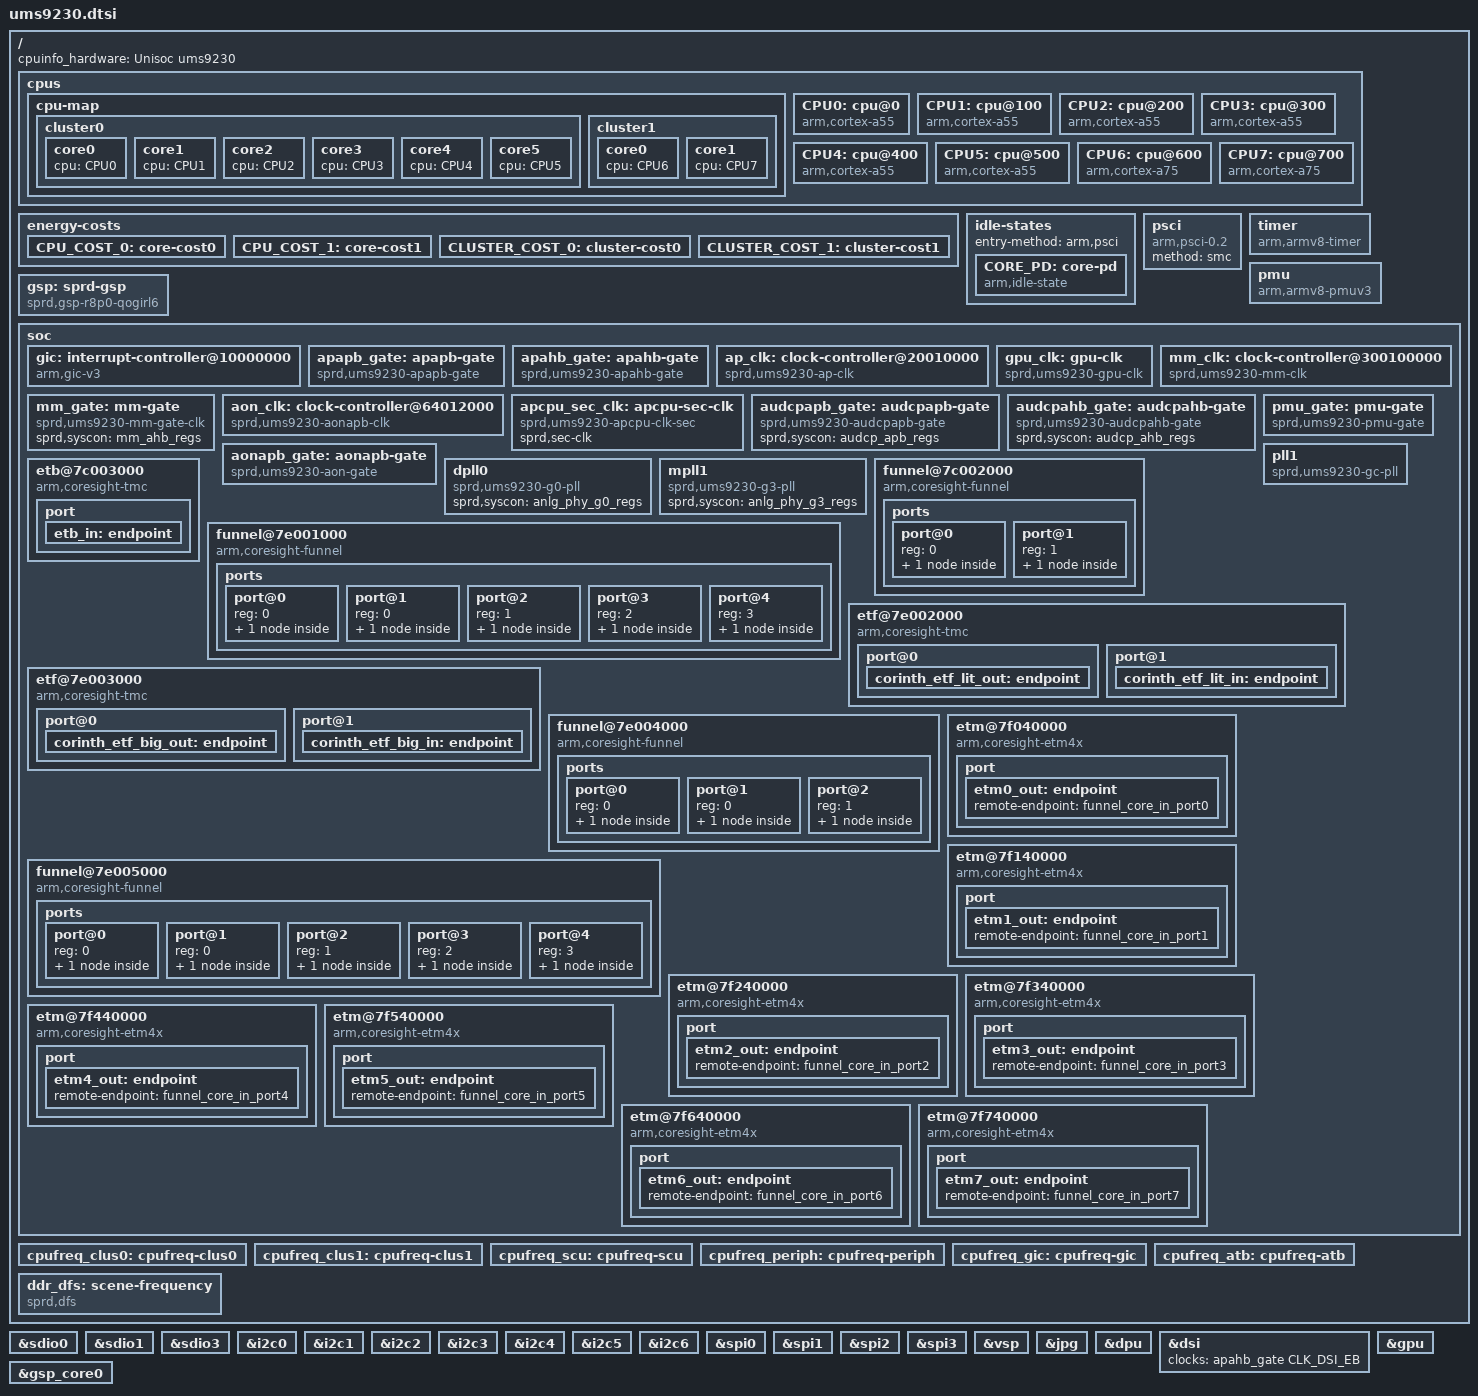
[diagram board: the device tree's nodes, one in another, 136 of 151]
// SPDX-License-Identifier: GPL-2.0-only
/*
 * Unisoc Qogirl6 platform DTS file
 *
 * Copyright (C) 2020, Unisoc Inc.
 */

#include <dt-bindings/interrupt-controller/arm-gic.h>
#include <dt-bindings/clock/sprd,ums9230-clk.h>
#include "qogirl6.dtsi"

/ {
	cpuinfo_hardware = "Unisoc ums9230";

	cpus {
		#address-cells = <2>;
		#size-cells = <0>;

		cpu-map {
			cluster0 {
				core0 {
					cpu = <&CPU0>;
				};
				core1 {
					cpu = <&CPU1>;
				};
				core2 {
					cpu = <&CPU2>;
				};
				core3 {
					cpu = <&CPU3>;
				};
				core4 {
					cpu = <&CPU4>;
				};
				core5 {
					cpu = <&CPU5>;
				};
			};
			cluster1 {
				core0 {
					cpu = <&CPU6>;
				};
				core1 {
					cpu = <&CPU7>;
				};
			};
		};

		CPU0: cpu@0 {
			device_type = "cpu";
			compatible = "arm,cortex-a55";
			reg = <0x0 0x0>;
			enable-method = "psci";
			cpu-idle-states = <&CORE_PD>;
			sched-energy-costs = <&CPU_COST_0 &CLUSTER_COST_0>;
			capacity-dmips-mhz = <544>;
			cpufreq-data-v1 = <&cpufreq_clus0>;
		};
		CPU1: cpu@100 {
			device_type = "cpu";
			compatible = "arm,cortex-a55";
			reg = <0x0 0x100>;
			enable-method = "psci";
			cpu-idle-states = <&CORE_PD>;
			sched-energy-costs = <&CPU_COST_0 &CLUSTER_COST_0>;
			capacity-dmips-mhz = <544>;
			cpufreq-data-v1 = <&cpufreq_clus0>;
		};
		CPU2: cpu@200 {
			device_type = "cpu";
			compatible = "arm,cortex-a55";
			reg = <0x0 0x200>;
			enable-method = "psci";
			cpu-idle-states = <&CORE_PD>;
			sched-energy-costs = <&CPU_COST_0 &CLUSTER_COST_0>;
			capacity-dmips-mhz = <544>;
			cpufreq-data-v1 = <&cpufreq_clus0>;
		};
		CPU3: cpu@300 {
			device_type = "cpu";
			compatible = "arm,cortex-a55";
			reg = <0x0 0x300>;
			enable-method = "psci";
			cpu-idle-states = <&CORE_PD>;
			sched-energy-costs = <&CPU_COST_0 &CLUSTER_COST_0>;
			capacity-dmips-mhz = <544>;
			cpufreq-data-v1 = <&cpufreq_clus0>;
		};
		CPU4: cpu@400 {
			device_type = "cpu";
			compatible = "arm,cortex-a55";
			reg = <0x0 0x400>;
			enable-method = "psci";
			cpu-idle-states = <&CORE_PD>;
			sched-energy-costs = <&CPU_COST_0 &CLUSTER_COST_0>;
			capacity-dmips-mhz = <544>;
			cpufreq-data-v1 = <&cpufreq_clus0>;
		};
		CPU5: cpu@500 {
			device_type = "cpu";
			compatible = "arm,cortex-a55";
			reg = <0x0 0x500>;
			enable-method = "psci";
			cpu-idle-states = <&CORE_PD>;
			sched-energy-costs = <&CPU_COST_0 &CLUSTER_COST_0>;
			capacity-dmips-mhz = <544>;
			cpufreq-data-v1 = <&cpufreq_clus0>;
		};
		CPU6: cpu@600 {
			device_type = "cpu";
			compatible = "arm,cortex-a75";
			reg = <0x0 0x600>;
			enable-method = "psci";
			cpu-idle-states = <&CORE_PD>;
			sched-energy-costs = <&CPU_COST_1 &CLUSTER_COST_1>;
			capacity-dmips-mhz = <1024>;
			cpufreq-data-v1 = <&cpufreq_clus1>;
		};
		CPU7: cpu@700 {
			device_type = "cpu";
			compatible = "arm,cortex-a75";
			reg = <0x0 0x700>;
			enable-method = "psci";
			cpu-idle-states = <&CORE_PD>;
			sched-energy-costs = <&CPU_COST_1 &CLUSTER_COST_1>;
			capacity-dmips-mhz = <1024>;
			cpufreq-data-v1 = <&cpufreq_clus1>;
		};
	};

	energy-costs {
		CPU_COST_0: core-cost0 {
			busy-cost-data = <
				164	44		//614MHz
				206	57		//768MHz
				258	74		//962MHz
				307	83		//1144MHz
				329	98		//1229MHz
				397	126		//1482MHz
				412	144		//1536MHz
				460	174		//1716MHz
				488	202		//1820MHz
			>;
			idle-cost-data = <
				30		/* ACTIVE-IDLE */
				30		/* WFI */
				0		/* CORE_PD */
			>;
			busy-cost-data-T616 = <
				164	44		//614MHz
				206	57		//768MHz
				258	74		//962MHz
				307	83		//1144MHz
				329	98		//1229MHz
				397	126		//1482MHz
				412	144		//1536MHz
				460	174		//1716MHz
				488	202		//1820MHz
			>;
			idle-cost-data-T616 = <
				30		/* ACTIVE-IDLE */
				30		/* WFI */
				0		/* CORE_PD */
			>;
		};
		CPU_COST_1: core-cost1 {
			busy-cost-data = <
				621	362		//1229MHz
				748	476		//1482MHz
				776	551		//1536MHz
				880	685		//1742MHz
				945	810		//1872MHz
				1024	964		//2028MHz
			>;
			idle-cost-data = <
				88		/* ACTIVE-IDLE */
				88		/* WFI */
				0		/* CORE_PD */
			>;
			busy-cost-data-T616 = <
				621	362		//1229MHz
				748	476		//1482MHz
				776	551		//1536MHz
				880	685		//1742MHz
				945	810		//1872MHz
				1024	964		//2028MHz
			>;
			idle-cost-data-T616 = <
				88		/* ACTIVE-IDLE */
				88		/* WFI */
				0		/* CORE_PD */
			>;
		};
		CLUSTER_COST_0: cluster-cost0 {
			busy-cost-data = <
				164	1		//614MHz
				206	2		//768MHz
				258	3		//962MHz
				307	4		//1144MHz
				329	5		//1229MHz
				397	6		//1482MHz
				412	7		//1536MHz
				460	8		//1716MHz
				488	9		//1820MHz
			>;
			idle-cost-data = <
				0		/* ACTIVE-IDLE */
				0		/* WFI */
				0		/* CORE_PD */
			>;
			busy-cost-data-T616 = <
				164	1		//614MHz
				206	2		//768MHz
				258	3		//962MHz
				307	4		//1144MHz
				329	5		//1229MHz
				397	6		//1482MHz
				412	7		//1536MHz
				460	8		//1716MHz
				488	9		//1820MHz
			>;
			idle-cost-data-T616 = <
				0		/* ACTIVE-IDLE */
				0		/* WFI */
				0		/* CORE_PD */
			>;
		};
		CLUSTER_COST_1: cluster-cost1 {
			busy-cost-data = <
				621	42		//1229MHz
				748	48		//1482MHz
				776	55		//1536MHz
				880	64		//1742MHz
				945	74		//1872MHz
				1024	84		//2028MHz
			>;
			idle-cost-data = <
				31		/* ACTIVE-IDLE */
				31		/* WFI */
				31		/* CORE_PD */
			>;
			busy-cost-data-T616 = <
				621	42		//1229MHz
				748	48		//1482MHz
				776	55		//1536MHz
				880	64		//1742MHz
				945	74		//1872MHz
				1024	84		//2028MHz
			>;
			idle-cost-data-T616 = <
				31		/* ACTIVE-IDLE */
				31		/* WFI */
				31		/* CORE_PD */
			>;
		};
	};

	idle-states {
		entry-method = "arm,psci";
		CORE_PD: core-pd {
			compatible = "arm,idle-state";
			entry-latency-us = <0x4000>;
			exit-latency-us = <0x4000>;
			min-residency-us = <0x10000>;
			local-timer-stop;
			arm,psci-suspend-param = <0x00010000>;
		};
	};

	psci {
		compatible = "arm,psci-0.2";
		method = "smc";
	};

	timer {
		compatible = "arm,armv8-timer";
		interrupts = <GIC_PPI 13 IRQ_TYPE_LEVEL_HIGH>, /* Physical Secure PPI */
			     <GIC_PPI 14 IRQ_TYPE_LEVEL_HIGH>, /* Physical Non-Secure PPI */
			     <GIC_PPI 11 IRQ_TYPE_LEVEL_HIGH>, /* Virtual PPI */
			     <GIC_PPI 10 IRQ_TYPE_LEVEL_HIGH>; /* Hipervisor PPI */
	};

	pmu {
		compatible = "arm,armv8-pmuv3";
		interrupts = <GIC_SPI 112 IRQ_TYPE_LEVEL_HIGH>,
				<GIC_SPI 113 IRQ_TYPE_LEVEL_HIGH>,
				<GIC_SPI 114 IRQ_TYPE_LEVEL_HIGH>,
				<GIC_SPI 115 IRQ_TYPE_LEVEL_HIGH>,
				<GIC_SPI 116 IRQ_TYPE_LEVEL_HIGH>,
				<GIC_SPI 117 IRQ_TYPE_LEVEL_HIGH>,
				<GIC_SPI 118 IRQ_TYPE_LEVEL_HIGH>,
				<GIC_SPI 119 IRQ_TYPE_LEVEL_HIGH>;
	};

	gsp: sprd-gsp {
		compatible = "sprd,gsp-r8p0-qogirl6";
		name = "sprd-gsp";
		core-cnt = <1>;
		io-cnt = <7>;
		cores = <&gsp_core0>;
	};

	soc {
		gic: interrupt-controller@10000000 {
			compatible = "arm,gic-v3";
			#interrupt-cells = <3>;
			#address-cells = <2>;
			#size-cells = <2>;
			ranges;
			redistributor-stride = <0x0 0x20000>;	/* 128KB stride */
			#redistributor-regions = <1>;
			interrupt-controller;
			reg = <0x0 0x10000000 0 0x20000>,	/* GICD */
				  <0x0 0x10040000 0 0x100000>;	/* GICR */
			interrupts = <GIC_PPI 9 IRQ_TYPE_LEVEL_HIGH>;
		};

		apapb_gate: apapb-gate {
			compatible = "sprd,ums9230-apapb-gate";
			sprd,syscon = <&ap_apb_regs>; /* 0x20000000 */
			clocks = <&ext_26m>;
			clock-names = "ext-26m";
			#clock-cells = <1>;
		};

		apahb_gate: apahb-gate {
			compatible = "sprd,ums9230-apahb-gate";
			sprd,syscon = <&ap_ahb_regs>; /* 0x20400000 */
			clocks = <&ext_26m>;
			clock-names = "ext-26m";
			#clock-cells = <1>;
		};

		ap_clk: clock-controller@20010000 {
			compatible = "sprd,ums9230-ap-clk";
			reg = <0 0x20010000 0 0x1000>;
			clocks = <&ext_26m>, <&dphy_273m>, <&dphy_204m8>;
			clock-names = "ext-26m", "dphy-273m", "dphy-204m8";
			#clock-cells = <1>;
		};

		gpu_clk: gpu-clk {
			compatible = "sprd,ums9230-gpu-clk";
			sprd,syscon = <&gpu_apb_regs>; /* 0x23000000 */
			clocks = <&ext_26m>;
			clock-names = "ext-26m";
			#clock-cells = <1>;
		};

		mm_clk: clock-controller@300100000 {
			compatible = "sprd,ums9230-mm-clk";
			reg = <0 0x30010000 0 0x1000>;
			clocks = <&ext_26m>;
			clock-names = "ext-26m";
			#clock-cells = <1>;
		};

		mm_gate: mm-gate {
			compatible = "sprd,ums9230-mm-gate-clk";
			sprd,syscon = <&mm_ahb_regs>; /* 0x30000000 */
			#clock-cells = <1>;
		};

		aon_clk: clock-controller@64012000 {
			compatible = "sprd,ums9230-aonapb-clk";
			reg = <0 0x64012000 0 0x1000>;
			clocks = <&ext_26m>, <&rco_100m>, <&ext_32k>;
			clock-names = "ext-26m", "rco-100m", "ext-32k";
			#clock-cells = <1>;
		};

		apcpu_sec_clk: apcpu-sec-clk {
			compatible = "sprd,ums9230-apcpu-clk-sec";
			sprd,sec-clk;
			#clock-cells = <1>;
	       };

		audcpapb_gate: audcpapb-gate {
			compatible = "sprd,ums9230-audcpapb-gate";
			sprd,syscon = <&audcp_apb_regs>; /* 0x5600d000 */
			#clock-cells = <1>;
		};

		audcpahb_gate: audcpahb-gate {
			compatible = "sprd,ums9230-audcpahb-gate";
			sprd,syscon = <&audcp_ahb_regs>; /* 0x56000000 */
			#clock-cells = <1>;
		};

		aonapb_gate: aonapb-gate {
			compatible = "sprd,ums9230-aon-gate";
			sprd,syscon = <&aon_apb_regs>; /* 0x64000000 */
			clocks = <&ext_26m>;
			clock-names = "ext-26m";
			#clock-cells = <1>;
		};

		pmu_gate: pmu-gate {
			compatible = "sprd,ums9230-pmu-gate";
			sprd,syscon = <&pmu_apb_regs>; /* 0x64020000 */
			clocks = <&ext_26m>;
			clock-names = "ext-26m";
			#clock-cells = <1>;
		};

		dpll0: dpll0 {
			compatible = "sprd,ums9230-g0-pll";
			sprd,syscon = <&anlg_phy_g0_regs>; /* 0x64550000 */
			#clock-cells = <1>;
		};

		mpll1: mpll1 {
			compatible = "sprd,ums9230-g3-pll";
			sprd,syscon = <&anlg_phy_g3_regs>; /* 0x64580000 */
			#clock-cells = <1>;
		};

		pll1: pll1 {
			compatible = "sprd,ums9230-gc-pll";
			sprd,syscon = <&anlg_phy_gc_regs>; /* 0x645a0000 */
			clocks = <&ext_26m>;
			clock-names = "ext-26m";
			#clock-cells = <1>;
		};

		/*    etm
		 * -> apcpu_funnel lit/big
		 * -> apcpu_etf lit/big
		 * -> funnel_to_soc
		 * -> soc_funnel
		 * -> soc_etf
		 */

		/* soc_funnel */
		funnel@7c002000 {
			compatible = "arm,coresight-funnel", "arm,primecell";
			reg = <0 0x7c002000 0 0x1000>;
			clocks = <&ext_26m>;
			clock-names = "apb_pclk";
			ports {
				#address-cells = <1>;
				#size-cells = <0>;

				port@0 {
					reg = <0>;
					funnel_soc_out_port: endpoint {
						remote-endpoint = <&etb_in>;
					};
				};

				port@1 {
					reg = <1>;
					funnel_soc_in_port: endpoint {
						slave-mode;
						remote-endpoint = <&funnel_corinth_out_port>;
					};
				};
			};
		};

		/* soc_etf */
		etb@7c003000 {
			compatible = "arm,coresight-tmc", "arm,primecell";
			reg = <0 0x7c003000 0 0x1000>;
			clocks = <&ext_26m>;
			clock-names = "apb_pclk";
			port {
				etb_in: endpoint {
					slave-mode;
					remote-endpoint = <&funnel_soc_out_port>;
				};
			};
		};

		/* apcpu funnel lit core3/4/5/7 */
		funnel@7e001000 {
			compatible = "arm,coresight-funnel", "arm,primecell";
			reg = <0 0x7e001000 0 0x1000>;
			clocks = <&ext_26m>;
			clock-names = "apb_pclk";

			ports {
				#address-cells = <1>;
				#size-cells = <0>;

				port@0 {
					reg = <0>;
					funnel_corinth_lit_out_port: endpoint {
						remote-endpoint = <&corinth_etf_lit_in>;
					};
				};

				port@1 {
					reg = <0>;
					funnel_core_in_port3: endpoint {
						slave-mode;
						remote-endpoint = <&etm3_out>;
					};
				};

				port@2 {
					reg = <1>;
					funnel_core_in_port4: endpoint {
						slave-mode;
						remote-endpoint = <&etm4_out>;
					};
				};

				port@3 {
					reg = <2>;
					funnel_core_in_port5: endpoint {
						slave-mode;
						remote-endpoint = <&etm5_out>;
					};
				};

				port@4 {
					reg = <3>;
					funnel_core_in_port7: endpoint {
						slave-mode;
						remote-endpoint = <&etm7_out>;
					};
				};
			};
		};

		/* apcpu lit etf */
		etf@7e002000 {
			compatible = "arm,coresight-tmc", "arm,primecell";
			reg = <0 0x7e002000 0 0x1000>;
			clocks = <&ext_26m>;
			clock-names = "apb_pclk";

			port@0 {
				corinth_etf_lit_out: endpoint {
					remote-endpoint = <&funnel_corinth_from_lit_in_port>;
				};
			};

			port@1 {
				corinth_etf_lit_in: endpoint {
					slave-mode;
					remote-endpoint = <&funnel_corinth_lit_out_port>;
				};
			};
		};

		/* apcpu big etf */
		etf@7e003000 {
			compatible = "arm,coresight-tmc", "arm,primecell";
			reg = <0 0x7e003000 0 0x1000>;
			clocks = <&ext_26m>;
			clock-names = "apb_pclk";

			port@0 {
				corinth_etf_big_out: endpoint {
					remote-endpoint = <&funnel_corinth_from_big_in_port>;
				};
			};

			port@1 {
				corinth_etf_big_in: endpoint {
					slave-mode;
					remote-endpoint = <&funnel_corinth_big_out_port>;
				};
			};
		};

		/* funnel to Soc */
		funnel@7e004000 {
			compatible = "arm,coresight-funnel", "arm,primecell";
			reg = <0 0x7e004000 0 0x1000>;
			clocks = <&ext_26m>;
			clock-names = "apb_pclk";
			ports {
				#address-cells = <1>;
				#size-cells = <0>;

				port@0 {
					reg = <0>;
					funnel_corinth_out_port: endpoint {
						remote-endpoint = <&funnel_soc_in_port>;
					};
				};

				port@1 {
					reg = <0>;
					funnel_corinth_from_lit_in_port: endpoint {
						slave-mode;
						remote-endpoint = <&corinth_etf_lit_out>;
					};
				};

				port@2 {
					reg = <1>;
					funnel_corinth_from_big_in_port: endpoint {
						slave-mode;
						remote-endpoint = <&corinth_etf_big_out>;
					};
				};
			};
		};

		/* apcpu funnel big core0/1/2/6 */
		funnel@7e005000 {
			compatible = "arm,coresight-funnel", "arm,primecell";
			reg = <0 0x7e005000 0 0x1000>;
			clocks = <&ext_26m>;
			clock-names = "apb_pclk";

			ports {
				#address-cells = <1>;
				#size-cells = <0>;

				port@0 {
					reg = <0>;
					funnel_corinth_big_out_port: endpoint {
						remote-endpoint = <&corinth_etf_big_in>;
					};
				};

				port@1 {
					reg = <0>;
					funnel_core_in_port0: endpoint {
						slave-mode;
						remote-endpoint = <&etm0_out>;
					};
				};

				port@2 {
					reg = <1>;
					funnel_core_in_port1: endpoint {
						slave-mode;
						remote-endpoint = <&etm1_out>;
					};
				};

				port@3 {
					reg = <2>;
					funnel_core_in_port2: endpoint {
						slave-mode;
						remote-endpoint = <&etm2_out>;
					};
				};

				port@4 {
					reg = <3>;
					funnel_core_in_port6: endpoint {
						slave-mode;
						remote-endpoint = <&etm6_out>;
					};
				};
			};
		};

		etm@7f040000 {
			compatible = "arm,coresight-etm4x", "arm,primecell";
			reg = <0 0x7f040000 0 0x1000>;
			cpu = <&CPU0>;
			clocks = <&ext_26m>, <&aon_clk CLK_CSSYS>, <&pll1 CLK_TWPLL_256M>;
			clock-names = "apb_pclk", "clk_cs", "cs_src";

			port {
				etm0_out: endpoint {
					remote-endpoint = <&funnel_core_in_port0>;
				};
			};
		};

		etm@7f140000 {
			compatible = "arm,coresight-etm4x", "arm,primecell";
			reg = <0 0x7f140000 0 0x1000>;
			cpu = <&CPU1>;
			clocks = <&ext_26m>, <&aon_clk CLK_CSSYS>, <&pll1 CLK_TWPLL_256M>;
			clock-names = "apb_pclk", "clk_cs", "cs_src";

			port {
				etm1_out: endpoint {
					remote-endpoint = <&funnel_core_in_port1>;
				};
			};
		};

		etm@7f240000 {
			compatible = "arm,coresight-etm4x", "arm,primecell";
			reg = <0 0x7f240000 0 0x1000>;
			cpu = <&CPU2>;
			clocks = <&ext_26m>, <&aon_clk CLK_CSSYS>, <&pll1 CLK_TWPLL_256M>;
			clock-names = "apb_pclk", "clk_cs", "cs_src";

			port {
				etm2_out: endpoint {
					remote-endpoint = <&funnel_core_in_port2>;
				};
			};
		};

		etm@7f340000 {
			compatible = "arm,coresight-etm4x", "arm,primecell";
			reg = <0 0x7f340000 0 0x1000>;
			cpu = <&CPU3>;
			clocks = <&ext_26m>, <&aon_clk CLK_CSSYS>, <&pll1 CLK_TWPLL_256M>;
			clock-names = "apb_pclk", "clk_cs", "cs_src";

			port {
				etm3_out: endpoint {
					remote-endpoint = <&funnel_core_in_port3>;
				};
			};
		};

		etm@7f440000 {
			compatible = "arm,coresight-etm4x", "arm,primecell";
			reg = <0 0x7f440000 0 0x1000>;
			cpu = <&CPU4>;
			clocks = <&ext_26m>, <&aon_clk CLK_CSSYS>, <&pll1 CLK_TWPLL_256M>;
			clock-names = "apb_pclk", "clk_cs", "cs_src";

			port {
				etm4_out: endpoint {
					remote-endpoint = <&funnel_core_in_port4>;
				};
			};
		};

		etm@7f540000 {
			compatible = "arm,coresight-etm4x", "arm,primecell";
			reg = <0 0x7f540000 0 0x1000>;
			cpu = <&CPU5>;
			clocks = <&ext_26m>, <&aon_clk CLK_CSSYS>, <&pll1 CLK_TWPLL_256M>;
			clock-names = "apb_pclk", "clk_cs", "cs_src";

			port {
				etm5_out: endpoint {
					remote-endpoint = <&funnel_core_in_port5>;
				};
			};
		};

		etm@7f640000 {
			compatible = "arm,coresight-etm4x", "arm,primecell";
			reg = <0 0x7f640000 0 0x1000>;
			cpu = <&CPU6>;
			clocks = <&ext_26m>, <&aon_clk CLK_CSSYS>, <&pll1 CLK_TWPLL_256M>;
			clock-names = "apb_pclk", "clk_cs", "cs_src";

			port {
				etm6_out: endpoint {
					remote-endpoint = <&funnel_core_in_port6>;
				};
			};
		};

		etm@7f740000 {
			compatible = "arm,coresight-etm4x", "arm,primecell";
			reg = <0 0x7f740000 0 0x1000>;
			cpu = <&CPU7>;
			clocks = <&ext_26m>, <&aon_clk CLK_CSSYS>, <&pll1 CLK_TWPLL_256M>;
			clock-names = "apb_pclk", "clk_cs", "cs_src";

			port {
				etm7_out: endpoint {
					remote-endpoint = <&funnel_core_in_port7>;
				};
			};
		};
	};

	cpufreq_clus0: cpufreq-clus0 {
		cpufreq-cluster-id = <0>;
		cpufreq-sub-clusters =  <&cpufreq_scu>,
					<&cpufreq_periph>,
					<&cpufreq_gic>;
		clock-latency = <50000>;
		voltage-tolerance = <6413>;
		operating-points = <
			/* kHZ   uV */
			1820000 1000000
			1716000 950000
			1536000 900000
			1482000 850000
			1228800 800000
			1144000	750000
			962000	750000
			768000	700000
			614400	650000
		>;
	};

	cpufreq_clus1: cpufreq-clus1 {
		cpufreq-cluster-id = <1>;
		cpufreq-sub-clusters =  <&cpufreq_scu>,
					<&cpufreq_periph>,
					<&cpufreq_gic>;
		clock-latency = <50000>;
		voltage-tolerance = <6413>;
		operating-points = <
			/* kHZ   uV */
			2028000 1000000
			1872000 950000
			1742000 900000
			1536000 850000
			1482000 800000
			1228800 750000
		>;
	};

	cpufreq_scu: cpufreq-scu {
		cpufreq-cluster-id = <2>;
		clock-latency = <50000>;
		voltage-tolerance = <0>;
		operating-points = <
			/* kHz   uV */
			1404000 1000000
			1326000 950000
			1222000 900000
			1118000 850000
			1014000 800000
			962000  750000
			768000  750000
			650000  700000
			546000  650000
		>;
	};

	cpufreq_periph: cpufreq-periph {
		cpufreq-cluster-id = <3>;
		clock-latency = <50000>;
		voltage-tolerance = <0>;
		operating-points = <
			/* kHZ  uV */
			768000 1000000
			512000 800000
			384000 750000
			256000 700000
			153600 650000
		>;
	};

	cpufreq_gic: cpufreq-gic {
		cpufreq-cluster-id = <4>;
		clock-latency = <50000>;
		voltage-tolerance = <0>;
		operating-points = <
			/* kHZ  uV */
			512000 800000
			384000 750000
			256000 750000
			192000 700000
			153600 650000
		>;
	};

	cpufreq_atb: cpufreq-atb {
		cpufreq-cluster-id = <5>;
		operating-points = <
			/* kHZ  uV */
			768000 1000000
			512000 800000
			384000 750000
			256000 650000
			153600 650000
		>;
	};

	ddr_dfs: scene-frequency {
		compatible = "sprd,dfs";
		freq-num = <8>;
		backdoor = <1866>;
	};
};

&sdio0 {
	clock-names = "sdio_clk", "sdio_clk_source",
		      "sdio_ahb_enable";
	clocks = <&ap_clk CLK_SDIO0_2X>,
		 <&mpll1 CLK_RPLL>,
		 <&apapb_gate CLK_SDIO0_EB>;
};

&sdio1 {
	clock-names = "sdio_clk","sdio_clk_source","sdio_ahb_enable";
	clocks = <&ap_clk CLK_SDIO1_2X>,
		 <&pll1 CLK_LPLL_409M6>,
		 <&apapb_gate CLK_SDIO1_EB>;
};

&sdio3 {
	clock-names = "sdio_clk","sdio_clk_source","sdio_ahb_enable";
	clocks = <&ap_clk CLK_EMMC_2X>,
		 <&mpll1 CLK_RPLL>,
		 <&apapb_gate CLK_EMMC_EB>;
};

&i2c0 {
	clock-names ="enable", "i2c", "source";
	clocks = <&apapb_gate CLK_I2C0_EB>,
		 <&ap_clk CLK_AP_I2C0>, <&ext_26m>;
};

&i2c1 {
	clock-names ="enable", "i2c", "source";
	clocks = <&apapb_gate CLK_I2C1_EB>,
		 <&ap_clk CLK_AP_I2C1>, <&ext_26m>;
};

&i2c2 {
	clock-names ="enable", "i2c", "source";
	clocks = <&apapb_gate CLK_I2C2_EB>,
		 <&ap_clk CLK_AP_I2C2>, <&ext_26m>;
};

&i2c3 {
	clock-names ="enable", "i2c", "source";
	clocks = <&apapb_gate CLK_I2C3_EB>,
		 <&ap_clk CLK_AP_I2C3>, <&ext_26m>;
};

&i2c4 {
	clock-names ="enable", "i2c", "source";
	clocks = <&apapb_gate CLK_I2C4_EB>,
		 <&ap_clk CLK_AP_I2C4>, <&ext_26m>;
};

&i2c5 {
	clock-names ="enable", "i2c", "source";
	clocks = <&apapb_gate CLK_I2C5_EB>,
		 <&ap_clk CLK_AP_I2C5>, <&ext_26m>;
};

&i2c6 {
	clock-names ="enable", "i2c", "source";
	clocks = <&apapb_gate CLK_I2C6_EB>,
		 <&ap_clk CLK_AP_I2C6>, <&ext_26m>;
};

&spi0 {
	clock-names = "enable", "spi", "source";
	clocks = <&apapb_gate CLK_SPI0_EB>,
		<&ap_clk CLK_AP_SPI0>, <&pll1 CLK_TWPLL_192M>;
};

&spi1 {
	clock-names = "enable", "spi", "source";
	clocks = <&apapb_gate CLK_SPI1_EB>,
		<&ap_clk CLK_AP_SPI1>, <&pll1 CLK_TWPLL_192M>;
};

&spi2 {
	clock-names = "enable", "spi", "source";
	clocks = <&apapb_gate CLK_SPI2_EB>,
		<&ap_clk CLK_AP_SPI2>, <&pll1 CLK_TWPLL_192M>;
};

&spi3 {
	clock-names = "enable", "spi", "source";
	clocks = <&apapb_gate CLK_SPI3_EB>,
		<&ap_clk CLK_AP_SPI3>, <&pll1 CLK_TWPLL_192M>;
};

&vsp {
	clock-names = "clk_ahb_gate_vsp_eb",
			"clk_src_256m",
			"clk_src_307m2",
			"clk_src_384m",
			"clk_vsp";
	clocks = <&apahb_gate CLK_VSP_EB>,
			<&pll1 CLK_TWPLL_256M>,
			<&pll1 CLK_TWPLL_307M2>,
			<&pll1 CLK_TWPLL_384M>,
			<&ap_clk CLK_VSP>;
};

&jpg {
	clock-names = "jpg_domain_eb",
			"jpg_dev_eb",
			"jpg_ckg_eb",
			"jpg_clk",
			"clk_src_76m8",
			"clk_src_128m",
			"clk_src_256m",
			"clk_src_384m";

	clocks = <&aonapb_gate CLK_MM_EB>,
			<&mm_gate CLK_MM_JPG_EB>,
			<&mm_gate CLK_MM_CKG_EB>,
			<&mm_clk CLK_JPG>,
			<&pll1 CLK_TWPLL_76M8>,
			<&pll1 CLK_TWPLL_128M>,
			<&pll1 CLK_TWPLL_256M>,
			<&pll1 CLK_TWPLL_384M>;
};

&dpu {
	clock-names = "clk_src_96m",
			"clk_src_128m",
			"clk_src_153m6",
			"clk_src_192m",
			"clk_src_256m",
			"clk_src_307m2",
			"clk_src_384m",
			"clk_dpu_core",
			"clk_dpu_dpi",
			"clk_ap_ahb_disp_eb";

	clocks = <&pll1 CLK_TWPLL_96M>,
		<&pll1 CLK_TWPLL_128M>,
		<&pll1 CLK_TWPLL_153M6>,
		<&pll1 CLK_TWPLL_192M>,
		<&pll1 CLK_TWPLL_256M>,
		<&pll1 CLK_TWPLL_307M2>,
		<&pll1 CLK_TWPLL_384M>,
		<&ap_clk CLK_DISPC0>,
		<&ap_clk CLK_DISPC0_DPI>,
		<&apahb_gate CLK_DISPC_EB>;
};

&dsi {
	clock-names = "clk_ap_ahb_dsi_eb";
	clocks = <&apahb_gate CLK_DSI_EB>;
};

&gsp_core0 {
	clock-names =	"clk_dpu_core_src",
			"clk_dpu_core",
			"clk_ap_ahb_disp_eb";

	clocks =	<&pll1 CLK_TWPLL_384M>,
			<&ap_clk CLK_DISPC0>,
			<&apahb_gate CLK_DISPC_EB>;
};

&gpu {
	clocks = <&aonapb_gate CLK_GPU_EB>,
	<&gpu_clk CLK_GPU_CORE_EB>,
	<&gpu_clk CLK_GPU_MEM_EB>,
	<&gpu_clk CLK_GPU_SYS_EB>,
	<&pll1 CLK_TWPLL_384M>,
	<&pll1 CLK_TWPLL_512M>,
	<&pll1 CLK_LPLL_614M4>,
	<&pll1 CLK_TWPLL_768M>,
	<&pll1 CLK_GPLL>;
};
